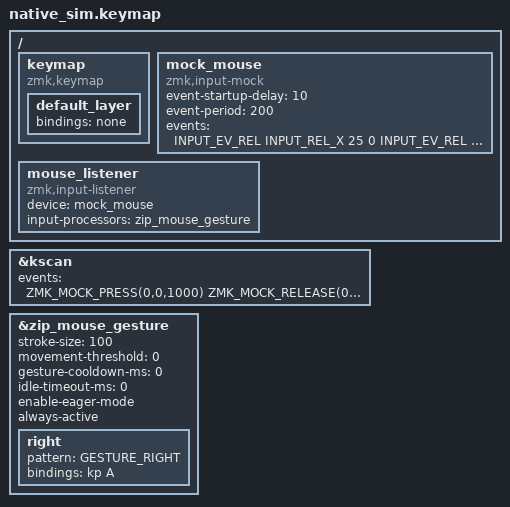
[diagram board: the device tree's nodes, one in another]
#include "../../behavior_keymap.dtsi"

/ {
    keymap {
        compatible = "zmk,keymap";
        default_layer {
            bindings = <&none>;
        };
    };

    mock_mouse: mock_mouse {
        compatible = "zmk,input-mock";
        event-startup-delay = <10>;
        event-period = <200>;
        events = <
            INPUT_EV_REL INPUT_REL_X 25 0
            INPUT_EV_REL INPUT_REL_X 25 0
            INPUT_EV_REL INPUT_REL_X 25 0
            INPUT_EV_REL INPUT_REL_X 25 1
        >;
    };

    mouse_listener: mouse_listener {
        compatible = "zmk,input-listener";
        device = <&mock_mouse>;
        input-processors = <&zip_mouse_gesture>;
    };
};

&kscan {
    events = <
        ZMK_MOCK_PRESS(0,0,1000)
        ZMK_MOCK_RELEASE(0,0,10)
    >;
};

&zip_mouse_gesture {
    stroke-size = <100>;
    movement-threshold = <0>;
    gesture-cooldown-ms = <0>;
    idle-timeout-ms = <0>;
    enable-eager-mode;
    always-active;

    right {
        pattern = <GESTURE_RIGHT>;
        bindings = <&kp A>;
    };
};
